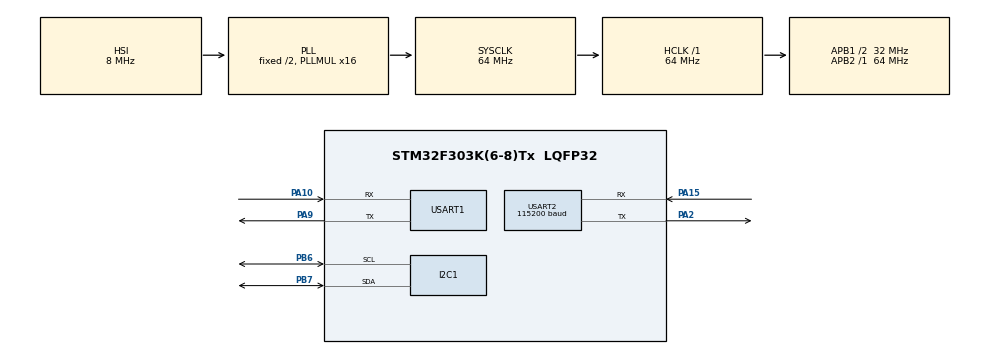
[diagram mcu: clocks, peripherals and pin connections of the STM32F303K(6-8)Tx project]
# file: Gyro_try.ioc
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Mcu.Family=STM32F3
Mcu.Name=STM32F303K(6-8)Tx
Mcu.Package=LQFP32
NVIC.PriorityGroup=NVIC_PRIORITYGROUP_4
PA10.Mode=Asynchronous
PA10.Signal=USART1_RX
PA13.GPIO_Label=SWDIO
PA13.Mode=Serial_Wire
PA13.Signal=SYS_JTMS-SWDIO
PA14.GPIO_Label=SWCLK
PA14.Mode=Serial_Wire
PA14.Signal=SYS_JTCK-SWCLK
PA15.Mode=Asynchronous
PA15.Signal=USART2_RX
PA2.Mode=Asynchronous
PA2.Signal=USART2_TX
PA9.Mode=Asynchronous
PA9.Signal=USART1_TX
PB6.Mode=I2C
PB6.Signal=I2C1_SCL
PB7.Mode=I2C
PB7.Signal=I2C1_SDA
PF0\ /\ OSC_IN.GPIO_Label=MCO
PF0\ /\ OSC_IN.Mode=HSE-External-Clock-Source
PF0\ /\ OSC_IN.Signal=RCC_OSC_IN
ProjectManager.HeapSize=0x200
ProjectManager.StackSize=0x400
ProjectManager.TargetToolchain=STM32CubeIDE
RCC.AHBFreq_Value=64000000
RCC.APB1CLKDivider=RCC_HCLK_DIV2
RCC.APB1Freq_Value=32000000
RCC.APB1TimFreq_Value=64000000
RCC.APB2Freq_Value=64000000
RCC.APB2TimFreq_Value=64000000
RCC.CortexFreq_Value=64000000
RCC.HCLKFreq_Value=64000000
RCC.HSE_VALUE=8000000
RCC.HSI_VALUE=8000000
RCC.PLLMUL=RCC_PLL_MUL16
RCC.SYSCLKFreq_VALUE=64000000
RCC.SYSCLKSourceVirtual=RCC_SYSCLKSOURCE_PLLCLK
USART1.VirtualMode-Asynchronous=VM_ASYNC
USART2.BaudRate=115200
USART2.VirtualMode-Asynchronous=VM_ASYNC
board=NUCLEO-F303K8

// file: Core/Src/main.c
/* USER CODE BEGIN Header */
/**
  ******************************************************************************
  * @file           : main.c
  * @brief          : Main program body
  ******************************************************************************
  * @attention
  *
  * Copyright (c) 2024 STMicroelectronics.
  * All rights reserved.
  *
  * This software is licensed under terms that can be found in the LICENSE file
  * in the root directory of this software component.
  * If no LICENSE file comes with this software, it is provided AS-IS.
  *
  ******************************************************************************
  */
/* USER CODE END Header */
#include "main.h"
#include <string.h>

I2C_HandleTypeDef hi2c1;

UART_HandleTypeDef huart1;
UART_HandleTypeDef huart2;

void SystemClock_Config(void);
static void MX_GPIO_Init(void);
static void MX_USART2_UART_Init(void);
static void MX_I2C1_Init(void);
static void MX_USART1_UART_Init(void);

int main(void)
{

  /* MCU Configuration--------------------------------------------------------*/

  /* Reset of all peripherals, Initializes the Flash interface and the Systick. */
  HAL_Init();

  /* Configure the system clock */
  SystemClock_Config();

  /* Initialize all configured peripherals */
  MX_GPIO_Init();
  MX_USART2_UART_Init();
  MX_I2C1_Init();
  MX_USART1_UART_Init();
  /* USER CODE BEGIN 2 */
  char str[100];
  char buf[10];
  extern ARM_DRIVER_I2C I2CDev_Driver;
  /* USER CODE END 2 */

  /* Infinite loop */
  /* USER CODE BEGIN WHILE */
  while (1)
  {
	  I2CDev_Driver.MasterTransmit(dev_addr, data, len, pending);
	  HAL_UART_Transmit(&huart2, (uint8_t*)"Hello", 10, 1000);
    /* USER CODE END WHILE */

  }
}

void SystemClock_Config(void)
{
  RCC_OscInitTypeDef RCC_OscInitStruct = {0};
  RCC_ClkInitTypeDef RCC_ClkInitStruct = {0};
  RCC_PeriphCLKInitTypeDef PeriphClkInit = {0};

  /** Initializes the RCC Oscillators according to the specified parameters
  * in the RCC_OscInitTypeDef structure.
  */
  RCC_OscInitStruct.OscillatorType = RCC_OSCILLATORTYPE_HSI;
  RCC_OscInitStruct.HSIState = RCC_HSI_ON;
  RCC_OscInitStruct.HSICalibrationValue = RCC_HSICALIBRATION_DEFAULT;
  RCC_OscInitStruct.PLL.PLLState = RCC_PLL_ON;
  RCC_OscInitStruct.PLL.PLLSource = RCC_PLLSOURCE_HSI;
  RCC_OscInitStruct.PLL.PLLMUL = RCC_PLL_MUL16;
  if (HAL_RCC_OscConfig(&RCC_OscInitStruct) != HAL_OK)
  {
    Error_Handler();
  }

  /** Initializes the CPU, AHB and APB buses clocks
  */
  RCC_ClkInitStruct.ClockType = RCC_CLOCKTYPE_HCLK|RCC_CLOCKTYPE_SYSCLK
                              |RCC_CLOCKTYPE_PCLK1|RCC_CLOCKTYPE_PCLK2;
  RCC_ClkInitStruct.SYSCLKSource = RCC_SYSCLKSOURCE_PLLCLK;
  RCC_ClkInitStruct.AHBCLKDivider = RCC_SYSCLK_DIV1;
  RCC_ClkInitStruct.APB1CLKDivider = RCC_HCLK_DIV2;
  RCC_ClkInitStruct.APB2CLKDivider = RCC_HCLK_DIV1;

  if (HAL_RCC_ClockConfig(&RCC_ClkInitStruct, FLASH_LATENCY_2) != HAL_OK)
  {
    Error_Handler();
  }
  PeriphClkInit.PeriphClockSelection = RCC_PERIPHCLK_USART1|RCC_PERIPHCLK_I2C1;
  PeriphClkInit.Usart1ClockSelection = RCC_USART1CLKSOURCE_PCLK1;
  PeriphClkInit.I2c1ClockSelection = RCC_I2C1CLKSOURCE_HSI;
  if (HAL_RCCEx_PeriphCLKConfig(&PeriphClkInit) != HAL_OK)
  {
    Error_Handler();
  }
}

static void MX_I2C1_Init(void)
{

  hi2c1.Instance = I2C1;
  hi2c1.Init.Timing = 0x2000090E;
  hi2c1.Init.OwnAddress1 = 0;
  hi2c1.Init.AddressingMode = I2C_ADDRESSINGMODE_7BIT;
  hi2c1.Init.DualAddressMode = I2C_DUALADDRESS_DISABLE;
  hi2c1.Init.OwnAddress2 = 0;
  hi2c1.Init.OwnAddress2Masks = I2C_OA2_NOMASK;
  hi2c1.Init.GeneralCallMode = I2C_GENERALCALL_DISABLE;
  hi2c1.Init.NoStretchMode = I2C_NOSTRETCH_DISABLE;
  if (HAL_I2C_Init(&hi2c1) != HAL_OK)
  {
    Error_Handler();
  }

  /** Configure Analogue filter
  */
  if (HAL_I2CEx_ConfigAnalogFilter(&hi2c1, I2C_ANALOGFILTER_ENABLE) != HAL_OK)
  {
    Error_Handler();
  }

  /** Configure Digital filter
  */
  if (HAL_I2CEx_ConfigDigitalFilter(&hi2c1, 0) != HAL_OK)
  {
    Error_Handler();
  }

}

static void MX_USART1_UART_Init(void)
{

  huart1.Instance = USART1;
  huart1.Init.BaudRate = 38400;
  huart1.Init.WordLength = UART_WORDLENGTH_8B;
  huart1.Init.StopBits = UART_STOPBITS_1;
  huart1.Init.Parity = UART_PARITY_NONE;
  huart1.Init.Mode = UART_MODE_TX_RX;
  huart1.Init.HwFlowCtl = UART_HWCONTROL_NONE;
  huart1.Init.OverSampling = UART_OVERSAMPLING_16;
  huart1.Init.OneBitSampling = UART_ONE_BIT_SAMPLE_DISABLE;
  huart1.AdvancedInit.AdvFeatureInit = UART_ADVFEATURE_NO_INIT;
  if (HAL_UART_Init(&huart1) != HAL_OK)
  {
    Error_Handler();
  }

}

static void MX_USART2_UART_Init(void)
{

  huart2.Instance = USART2;
  huart2.Init.BaudRate = 115200;
  huart2.Init.WordLength = UART_WORDLENGTH_8B;
  huart2.Init.StopBits = UART_STOPBITS_1;
  huart2.Init.Parity = UART_PARITY_NONE;
  huart2.Init.Mode = UART_MODE_TX_RX;
  huart2.Init.HwFlowCtl = UART_HWCONTROL_NONE;
  huart2.Init.OverSampling = UART_OVERSAMPLING_16;
  huart2.Init.OneBitSampling = UART_ONE_BIT_SAMPLE_DISABLE;
  huart2.AdvancedInit.AdvFeatureInit = UART_ADVFEATURE_NO_INIT;
  if (HAL_UART_Init(&huart2) != HAL_OK)
  {
    Error_Handler();
  }

}

static void MX_GPIO_Init(void)
{

  /* GPIO Ports Clock Enable */
  __HAL_RCC_GPIOF_CLK_ENABLE();
  __HAL_RCC_GPIOA_CLK_ENABLE();
  __HAL_RCC_GPIOB_CLK_ENABLE();

}

void Error_Handler(void)
{
  __disable_irq();
  while (1)
  {
  }
}
